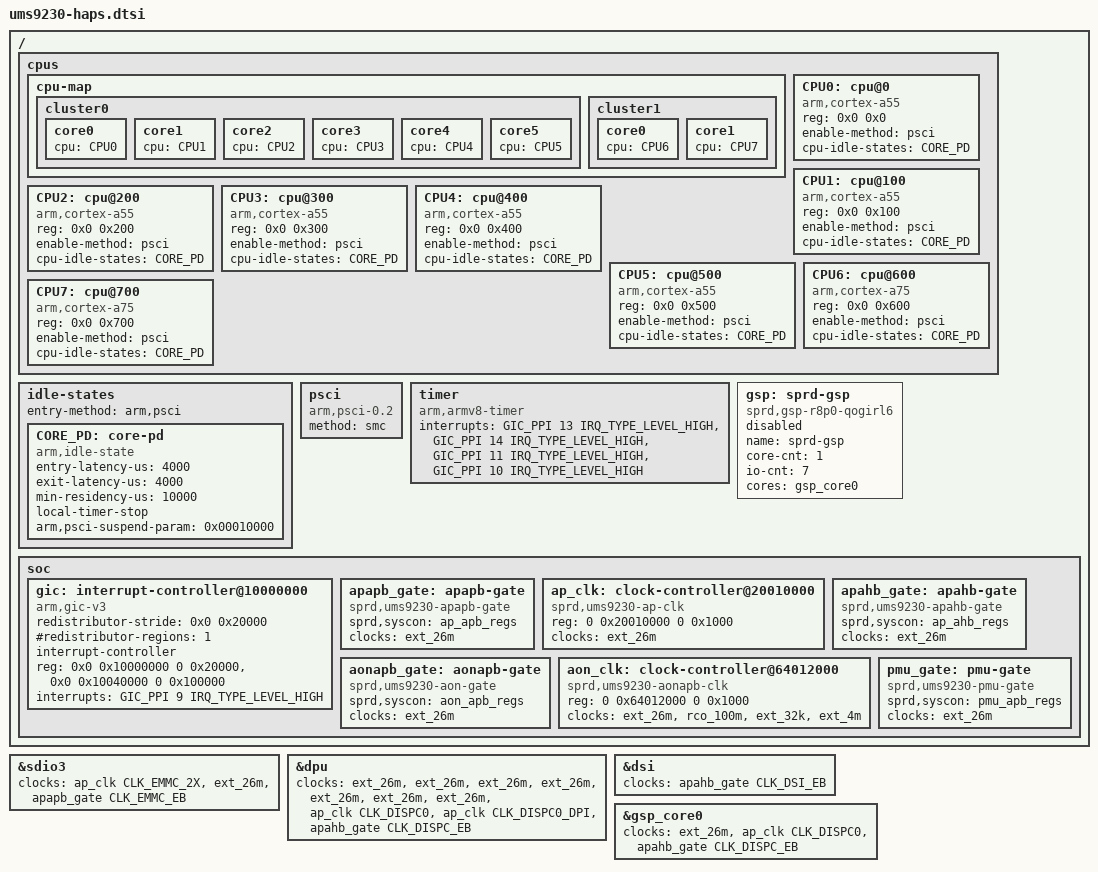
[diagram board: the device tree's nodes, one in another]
// SPDX-License-Identifier: GPL-2.0-only
/*
 * Unisoc Qogirl6 platform DTS file
 *
 * Copyright (C) 2020, Unisoc Inc.
 */

#include <dt-bindings/interrupt-controller/arm-gic.h>
#include <dt-bindings/clock/sprd,ums9230-clk.h>
#include "qogirl6-haps.dtsi"

/ {
	cpus {
		#address-cells = <2>;
		#size-cells = <0>;

		cpu-map {
			cluster0 {
				core0 {
					cpu = <&CPU0>;
				};
				core1 {
					cpu = <&CPU1>;
				};
				core2 {
					cpu = <&CPU2>;
				};
				core3 {
					cpu = <&CPU3>;
				};
				core4 {
					cpu = <&CPU4>;
				};
				core5 {
					cpu = <&CPU5>;
				};
			};
			cluster1 {
				core0{
					cpu = <&CPU6>;
				};
				core1{
					cpu = <&CPU7>;
				};
			};
		};

		CPU0: cpu@0 {
			device_type = "cpu";
			compatible = "arm,cortex-a55";
			reg = <0x0 0x0>;
			enable-method = "psci";
			cpu-idle-states = <&CORE_PD>;
		};
		CPU1: cpu@100 {
			device_type = "cpu";
			compatible = "arm,cortex-a55";
			reg = <0x0 0x100>;
			enable-method = "psci";
			cpu-idle-states = <&CORE_PD>;
		};
		CPU2: cpu@200 {
			device_type = "cpu";
			compatible = "arm,cortex-a55";
			reg = <0x0 0x200>;
			enable-method = "psci";
			cpu-idle-states = <&CORE_PD>;
		};
		CPU3: cpu@300 {
			device_type = "cpu";
			compatible = "arm,cortex-a55";
			reg = <0x0 0x300>;
			enable-method = "psci";
			cpu-idle-states = <&CORE_PD>;
		};
		CPU4: cpu@400 {
			device_type = "cpu";
			compatible = "arm,cortex-a55";
			reg = <0x0 0x400>;
			enable-method = "psci";
			cpu-idle-states = <&CORE_PD>;
		};
		CPU5: cpu@500 {
			device_type = "cpu";
			compatible = "arm,cortex-a55";
			reg = <0x0 0x500>;
			enable-method = "psci";
			cpu-idle-states = <&CORE_PD>;
		};
		CPU6: cpu@600 {
			device_type = "cpu";
			compatible = "arm,cortex-a75";
			reg = <0x0 0x600>;
			enable-method = "psci";
			cpu-idle-states = <&CORE_PD>;
		};
		CPU7: cpu@700 {
			device_type = "cpu";
			compatible = "arm,cortex-a75";
			reg = <0x0 0x700>;
			enable-method = "psci";
			cpu-idle-states = <&CORE_PD>;
		};
	};

	idle-states {
		entry-method = "arm,psci";
		CORE_PD: core-pd {
			compatible = "arm,idle-state";
			entry-latency-us = <4000>;
			exit-latency-us = <4000>;
			min-residency-us = <10000>;
			local-timer-stop;
			arm,psci-suspend-param = <0x00010000>;
		};
	};

	psci {
		compatible = "arm,psci-0.2";
		method = "smc";
	};

	timer {
		compatible = "arm,armv8-timer";
		interrupts = <GIC_PPI 13 IRQ_TYPE_LEVEL_HIGH>, /* Physical Secure PPI */
			     <GIC_PPI 14 IRQ_TYPE_LEVEL_HIGH>, /* Physical Non-Secure PPI */
			     <GIC_PPI 11 IRQ_TYPE_LEVEL_HIGH>, /* Virtual PPI */
			     <GIC_PPI 10 IRQ_TYPE_LEVEL_HIGH>; /* Hipervisor PPI */
	};

	gsp: sprd-gsp {
		compatible = "sprd,gsp-r8p0-qogirl6";
		name = "sprd-gsp";
		core-cnt = <1>;
		io-cnt = <7>;
		cores = <&gsp_core0>;
		status = "disabled";
	};

	soc {
		gic: interrupt-controller@10000000 {
			compatible = "arm,gic-v3";
			#interrupt-cells = <3>;
			#address-cells = <2>;
			#size-cells = <2>;
			ranges;
			redistributor-stride = <0x0 0x20000>;	/* 128KB stride */
			#redistributor-regions = <1>;
			interrupt-controller;
			reg = <0x0 0x10000000 0 0x20000>,	/* GICD */
				  <0x0 0x10040000 0 0x100000>;	/* GICR */
			interrupts = <GIC_PPI 9 IRQ_TYPE_LEVEL_HIGH>;
		};

		apapb_gate: apapb-gate {
			compatible = "sprd,ums9230-apapb-gate";
			sprd,syscon = <&ap_apb_regs>; /* 0x20000000 */
			clocks = <&ext_26m>;
			clock-names = "ext-26m";
			#clock-cells = <1>;
		};

		ap_clk: clock-controller@20010000 {
			compatible = "sprd,ums9230-ap-clk";
			reg = <0 0x20010000 0 0x1000>;
			clocks = <&ext_26m>;
			clock-names = "ext-26m";
			#clock-cells = <1>;
		};

		apahb_gate: apahb-gate {
			compatible = "sprd,ums9230-apahb-gate";
			sprd,syscon = <&ap_ahb_regs>; /* 0x20400000 */
			clocks = <&ext_26m>;
			clock-names = "ext-26m";
			#clock-cells = <1>;
		};

		aonapb_gate: aonapb-gate {
			compatible = "sprd,ums9230-aon-gate";
			sprd,syscon = <&aon_apb_regs>; /* 0x64000000 */
			clocks = <&ext_26m>;
			clock-names = "ext-26m";
			#clock-cells = <1>;
		};

		aon_clk: clock-controller@64012000 {
			compatible = "sprd,ums9230-aonapb-clk";
			reg = <0 0x64012000 0 0x1000>;
			clocks = <&ext_26m>, <&rco_100m>, <&ext_32k>,
				 <&ext_4m>;
			clock-names = "ext-26m", "rco-100m", "ext-32k",
					  "ext-4m";
			#clock-cells = <1>;
		};

		pmu_gate: pmu-gate {
			compatible = "sprd,ums9230-pmu-gate";
			sprd,syscon = <&pmu_apb_regs>; /* 0x64020000 */
			clocks = <&ext_26m>;
			clock-names = "ext-26m";
			#clock-cells = <1>;
		};
	};
};

&sdio3 {
	clock-names = "sdio_clk","sdio_clk_source","sdio_ahb_enable";
	clocks = <&ap_clk CLK_EMMC_2X>,
		 <&ext_26m>,
		 <&apapb_gate CLK_EMMC_EB>;
};

&dpu {
	clock-names = "clk_src_96m",
			"clk_src_128m",
			"clk_src_153m6",
			"clk_src_192m",
			"clk_src_256m",
			"clk_src_307m2",
			"clk_src_384m",
			"clk_dpu_core",
			"clk_dpu_dpi",
			"clk_ap_ahb_disp_eb";

	clocks = <&ext_26m>,
		<&ext_26m>,
		<&ext_26m>,
		<&ext_26m>,
		<&ext_26m>,
		<&ext_26m>,
		<&ext_26m>,
		<&ap_clk CLK_DISPC0>,
		<&ap_clk CLK_DISPC0_DPI>,
		<&apahb_gate CLK_DISPC_EB>;
};

&dsi {
	clock-names = "clk_ap_ahb_dsi_eb";
	clocks = <&apahb_gate CLK_DSI_EB>;
};

&gsp_core0 {
	clock-names =	"clk_dpu_core_src",
			"clk_dpu_core",
			"clk_ap_ahb_disp_eb";

	clocks =	<&ext_26m>,
			<&ap_clk CLK_DISPC0>,
			<&apahb_gate CLK_DISPC_EB>;
};
